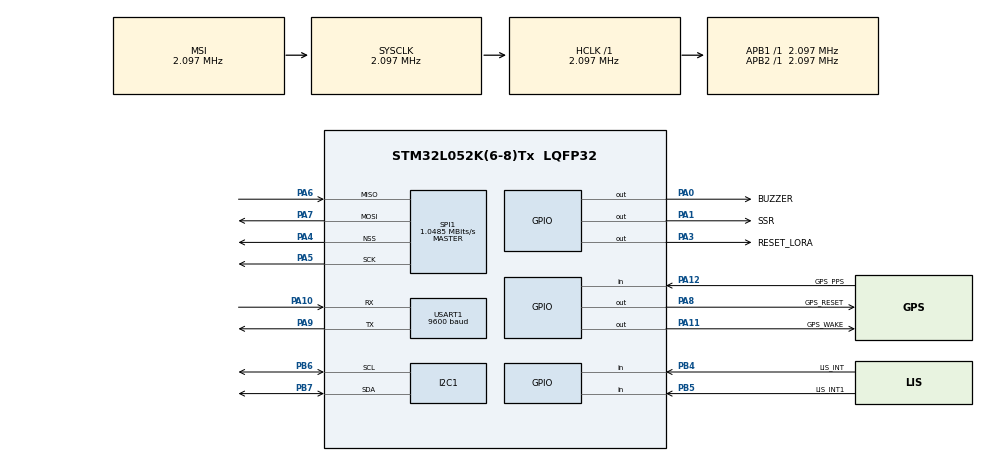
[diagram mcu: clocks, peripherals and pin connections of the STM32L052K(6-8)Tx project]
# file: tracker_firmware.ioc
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Mcu.Family=STM32L0
Mcu.Name=STM32L052K(6-8)Tx
Mcu.Package=LQFP32
PA0.GPIO_Label=BUZZER
PA0.GPIO_Speed=GPIO_SPEED_FREQ_VERY_HIGH
PA0.PinState=GPIO_PIN_RESET
PA0.Signal=GPIO_Output
PA1.GPIO_Label=SSR
PA1.GPIO_Speed=GPIO_SPEED_FREQ_VERY_HIGH
PA1.Signal=GPIO_Output
PA10.Mode=Multiprocessor_communication
PA10.Signal=USART1_RX
PA11.GPIO_Label=GPS_WAKE
PA11.Signal=GPIO_Output
PA12.GPIO_Label=GPS_PPS
PA12.Signal=GPIO_Input
PA13.Mode=Serial_Wire
PA13.Signal=SYS_SWDIO
PA14.Mode=Serial_Wire
PA14.Signal=SYS_SWCLK
PA3.GPIO_Label=RESET_LORA
PA3.Signal=GPIO_Output
PA4.Mode=NSS_Signal_Hard_Output
PA4.Signal=SPI1_NSS
PA5.Mode=Full_Duplex_Master
PA5.Signal=SPI1_SCK
PA6.Mode=Full_Duplex_Master
PA6.Signal=SPI1_MISO
PA7.Mode=Full_Duplex_Master
PA7.Signal=SPI1_MOSI
PA8.GPIO_Label=GPS_RESET
PA8.Signal=GPIO_Output
PA9.Mode=Multiprocessor_communication
PA9.Signal=USART1_TX
PB4.GPIO_Label=LIS_INT
PB4.Signal=GPIO_Input
PB5.GPIO_Label=LIS_INT1
PB5.Signal=GPIO_Input
PB6.GPIO_Pu=GPIO_PULLUP
PB6.Mode=I2C
PB6.Signal=I2C1_SCL
PB7.GPIO_Pu=GPIO_PULLUP
PB7.Mode=I2C
PB7.Signal=I2C1_SDA
PC14-OSC32_IN.Mode=LSE-External-Oscillator
PC14-OSC32_IN.Signal=RCC_OSC32_IN
PC15-OSC32_OUT.Mode=LSE-External-Oscillator
PC15-OSC32_OUT.Signal=RCC_OSC32_OUT
ProjectManager.HeapSize=0x200
ProjectManager.StackSize=0x400
ProjectManager.TargetToolchain=STM32CubeIDE
RCC.AHBFreq_Value=2097000
RCC.APB1Freq_Value=2097000
RCC.APB1TimFreq_Value=2097000
RCC.APB2Freq_Value=2097000
RCC.APB2TimFreq_Value=2097000
RCC.HSI16_VALUE=16000000
RCC.HSI48_VALUE=48000000
RCC.HSI_VALUE=16000000
RCC.MSI_VALUE=2097000
RCC.SYSCLKFreq_VALUE=2097000
RCC.VCOOutputFreq_Value=48000000
SPI1.CalculateBaudRate=1.0485 MBits/s
SPI1.Direction=SPI_DIRECTION_2LINES
SPI1.Mode=SPI_MODE_MASTER
SPI1.VirtualNSS=VM_NSSHARD
SPI1.VirtualType=VM_MASTER
USART1.BaudRate=9600
USART1.VirtualMode-Multiprocessor_communication=VM_ASYNC
VP_RTC_VS_RTC_Activate.Mode=RTC_Enabled
VP_RTC_VS_RTC_Calendar.Mode=RTC_Calendar
board=custom

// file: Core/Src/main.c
/* USER CODE BEGIN Header */
/**
  ******************************************************************************
  * @file           : main.c
  * @brief          : Main program body
  ******************************************************************************
  * @attention
  *
  * <h2><center>&copy; Copyright (c) 2021 STMicroelectronics.
  * All rights reserved.</center></h2>
  *
  * This software component is licensed by ST under BSD 3-Clause license,
  * the "License"; You may not use this file except in compliance with the
  * License. You may obtain a copy of the License at:
  *                        opensource.org/licenses/BSD-3-Clause
  *
  ******************************************************************************
  */
/* USER CODE END Header */
#include "main.h"
#include "tracker.h"

I2C_HandleTypeDef hi2c1;

RTC_HandleTypeDef hrtc;

SPI_HandleTypeDef hspi1;

UART_HandleTypeDef huart1;

void SystemClock_Config(void);
static void MX_GPIO_Init(void);
static void MX_I2C1_Init(void);
static void MX_RTC_Init(void);
static void MX_SPI1_Init(void);
static void MX_USART1_UART_Init(void);

int main(void)
{

  /* MCU Configuration--------------------------------------------------------*/

  /* Reset of all peripherals, Initializes the Flash interface and the Systick. */
  HAL_Init();

  /* Configure the system clock */
  SystemClock_Config();

  /* Initialize all configured peripherals */
  MX_GPIO_Init();
  MX_I2C1_Init();
  MX_RTC_Init();
  MX_SPI1_Init();
  MX_USART1_UART_Init();
  /* USER CODE BEGIN 2 */
  int errorcode = SetTime(0X0, 0X1, 0X0, 0X1, 0X9, 0X1, 0X1);

  /* USER CODE END 2 */

  /* Infinite loop */
  while (1)
  {

  }
}

void SystemClock_Config(void)
{
  RCC_OscInitTypeDef RCC_OscInitStruct = {0};
  RCC_ClkInitTypeDef RCC_ClkInitStruct = {0};
  RCC_PeriphCLKInitTypeDef PeriphClkInit = {0};

  /** Configure the main internal regulator output voltage
  */
  __HAL_PWR_VOLTAGESCALING_CONFIG(PWR_REGULATOR_VOLTAGE_SCALE1);
  /** Initializes the RCC Oscillators according to the specified parameters
  * in the RCC_OscInitTypeDef structure.
  */
  RCC_OscInitStruct.OscillatorType = RCC_OSCILLATORTYPE_LSI|RCC_OSCILLATORTYPE_MSI;
  RCC_OscInitStruct.LSIState = RCC_LSI_ON;
  RCC_OscInitStruct.MSIState = RCC_MSI_ON;
  RCC_OscInitStruct.MSICalibrationValue = 0;
  RCC_OscInitStruct.MSIClockRange = RCC_MSIRANGE_5;
  RCC_OscInitStruct.PLL.PLLState = RCC_PLL_NONE;
  if (HAL_RCC_OscConfig(&RCC_OscInitStruct) != HAL_OK)
  {
    Error_Handler();
  }
  /** Initializes the CPU, AHB and APB buses clocks
  */
  RCC_ClkInitStruct.ClockType = RCC_CLOCKTYPE_HCLK|RCC_CLOCKTYPE_SYSCLK
                              |RCC_CLOCKTYPE_PCLK1|RCC_CLOCKTYPE_PCLK2;
  RCC_ClkInitStruct.SYSCLKSource = RCC_SYSCLKSOURCE_MSI;
  RCC_ClkInitStruct.AHBCLKDivider = RCC_SYSCLK_DIV1;
  RCC_ClkInitStruct.APB1CLKDivider = RCC_HCLK_DIV1;
  RCC_ClkInitStruct.APB2CLKDivider = RCC_HCLK_DIV1;

  if (HAL_RCC_ClockConfig(&RCC_ClkInitStruct, FLASH_LATENCY_0) != HAL_OK)
  {
    Error_Handler();
  }
  PeriphClkInit.PeriphClockSelection = RCC_PERIPHCLK_USART1|RCC_PERIPHCLK_I2C1
                              |RCC_PERIPHCLK_RTC;
  PeriphClkInit.Usart1ClockSelection = RCC_USART1CLKSOURCE_PCLK2;
  PeriphClkInit.I2c1ClockSelection = RCC_I2C1CLKSOURCE_PCLK1;
  PeriphClkInit.RTCClockSelection = RCC_RTCCLKSOURCE_LSI;
  if (HAL_RCCEx_PeriphCLKConfig(&PeriphClkInit) != HAL_OK)
  {
    Error_Handler();
  }
}

static void MX_I2C1_Init(void)
{

  hi2c1.Instance = I2C1;
  hi2c1.Init.Timing = 0x00000708;
  hi2c1.Init.OwnAddress1 = 0;
  hi2c1.Init.AddressingMode = I2C_ADDRESSINGMODE_7BIT;
  hi2c1.Init.DualAddressMode = I2C_DUALADDRESS_DISABLE;
  hi2c1.Init.OwnAddress2 = 0;
  hi2c1.Init.OwnAddress2Masks = I2C_OA2_NOMASK;
  hi2c1.Init.GeneralCallMode = I2C_GENERALCALL_DISABLE;
  hi2c1.Init.NoStretchMode = I2C_NOSTRETCH_DISABLE;
  if (HAL_I2C_Init(&hi2c1) != HAL_OK)
  {
    Error_Handler();
  }
  /** Configure Analogue filter
  */
  if (HAL_I2CEx_ConfigAnalogFilter(&hi2c1, I2C_ANALOGFILTER_ENABLE) != HAL_OK)
  {
    Error_Handler();
  }
  /** Configure Digital filter
  */
  if (HAL_I2CEx_ConfigDigitalFilter(&hi2c1, 0) != HAL_OK)
  {
    Error_Handler();
  }

}

static void MX_RTC_Init(void)
{

  RTC_TimeTypeDef sTime = {0};
  RTC_DateTypeDef sDate = {0};

  /** Initialize RTC Only
  */
  hrtc.Instance = RTC;
  hrtc.Init.HourFormat = RTC_HOURFORMAT_24;
  hrtc.Init.AsynchPrediv = 127;
  hrtc.Init.SynchPrediv = 255;
  hrtc.Init.OutPut = RTC_OUTPUT_DISABLE;
  hrtc.Init.OutPutRemap = RTC_OUTPUT_REMAP_NONE;
  hrtc.Init.OutPutPolarity = RTC_OUTPUT_POLARITY_HIGH;
  hrtc.Init.OutPutType = RTC_OUTPUT_TYPE_OPENDRAIN;
  if (HAL_RTC_Init(&hrtc) != HAL_OK)
  {
    Error_Handler();
  }

  /** Initialize RTC and set the Time and Date
  */
  sTime.Hours = 0x0;
  sTime.Minutes = 0x0;
  sTime.Seconds = 0x0;
  sTime.DayLightSaving = RTC_DAYLIGHTSAVING_NONE;
  sTime.StoreOperation = RTC_STOREOPERATION_RESET;
  if (HAL_RTC_SetTime(&hrtc, &sTime, RTC_FORMAT_BCD) != HAL_OK)
  {
    Error_Handler();
  }
  sDate.WeekDay = RTC_WEEKDAY_MONDAY;
  sDate.Month = RTC_MONTH_JANUARY;
  sDate.Date = 0x1;
  sDate.Year = 0x0;

  if (HAL_RTC_SetDate(&hrtc, &sDate, RTC_FORMAT_BCD) != HAL_OK)
  {
    Error_Handler();
  }

}

static void MX_SPI1_Init(void)
{

  /* SPI1 parameter configuration*/
  hspi1.Instance = SPI1;
  hspi1.Init.Mode = SPI_MODE_MASTER;
  hspi1.Init.Direction = SPI_DIRECTION_2LINES;
  hspi1.Init.DataSize = SPI_DATASIZE_8BIT;
  hspi1.Init.CLKPolarity = SPI_POLARITY_LOW;
  hspi1.Init.CLKPhase = SPI_PHASE_1EDGE;
  hspi1.Init.NSS = SPI_NSS_HARD_OUTPUT;
  hspi1.Init.BaudRatePrescaler = SPI_BAUDRATEPRESCALER_2;
  hspi1.Init.FirstBit = SPI_FIRSTBIT_MSB;
  hspi1.Init.TIMode = SPI_TIMODE_DISABLE;
  hspi1.Init.CRCCalculation = SPI_CRCCALCULATION_DISABLE;
  hspi1.Init.CRCPolynomial = 7;
  if (HAL_SPI_Init(&hspi1) != HAL_OK)
  {
    Error_Handler();
  }

}

static void MX_USART1_UART_Init(void)
{

  huart1.Instance = USART1;
  huart1.Init.BaudRate = 9600;
  huart1.Init.WordLength = UART_WORDLENGTH_8B;
  huart1.Init.StopBits = UART_STOPBITS_1;
  huart1.Init.Parity = UART_PARITY_NONE;
  huart1.Init.Mode = UART_MODE_TX_RX;
  huart1.Init.HwFlowCtl = UART_HWCONTROL_NONE;
  huart1.Init.OverSampling = UART_OVERSAMPLING_16;
  huart1.Init.OneBitSampling = UART_ONE_BIT_SAMPLE_DISABLE;
  huart1.AdvancedInit.AdvFeatureInit = UART_ADVFEATURE_NO_INIT;
  if (HAL_MultiProcessor_Init(&huart1, 0, UART_WAKEUPMETHOD_IDLELINE) != HAL_OK)
  {
    Error_Handler();
  }

}

static void MX_GPIO_Init(void)
{
  GPIO_InitTypeDef GPIO_InitStruct = {0};

  /* GPIO Ports Clock Enable */
  __HAL_RCC_GPIOC_CLK_ENABLE();
  __HAL_RCC_GPIOA_CLK_ENABLE();
  __HAL_RCC_GPIOB_CLK_ENABLE();

  /*Configure GPIO pin Output Level */
  HAL_GPIO_WritePin(GPIOA, BUZZER_Pin|SSR_Pin|RESET_LORA_Pin|GPS_RESET_Pin
                          |GPS_WAKE_Pin, GPIO_PIN_RESET);

  /*Configure GPIO pins : BUZZER_Pin SSR_Pin */
  GPIO_InitStruct.Pin = BUZZER_Pin|SSR_Pin;
  GPIO_InitStruct.Mode = GPIO_MODE_OUTPUT_PP;
  GPIO_InitStruct.Pull = GPIO_NOPULL;
  GPIO_InitStruct.Speed = GPIO_SPEED_FREQ_VERY_HIGH;
  HAL_GPIO_Init(GPIOA, &GPIO_InitStruct);

  /*Configure GPIO pins : RESET_LORA_Pin GPS_RESET_Pin GPS_WAKE_Pin */
  GPIO_InitStruct.Pin = RESET_LORA_Pin|GPS_RESET_Pin|GPS_WAKE_Pin;
  GPIO_InitStruct.Mode = GPIO_MODE_OUTPUT_PP;
  GPIO_InitStruct.Pull = GPIO_NOPULL;
  GPIO_InitStruct.Speed = GPIO_SPEED_FREQ_LOW;
  HAL_GPIO_Init(GPIOA, &GPIO_InitStruct);

  /*Configure GPIO pin : GPS_PPS_Pin */
  GPIO_InitStruct.Pin = GPS_PPS_Pin;
  GPIO_InitStruct.Mode = GPIO_MODE_INPUT;
  GPIO_InitStruct.Pull = GPIO_NOPULL;
  HAL_GPIO_Init(GPS_PPS_GPIO_Port, &GPIO_InitStruct);

  /*Configure GPIO pins : LIS_INT_Pin LIS_INT1_Pin */
  GPIO_InitStruct.Pin = LIS_INT_Pin|LIS_INT1_Pin;
  GPIO_InitStruct.Mode = GPIO_MODE_INPUT;
  GPIO_InitStruct.Pull = GPIO_NOPULL;
  HAL_GPIO_Init(GPIOB, &GPIO_InitStruct);

}

void Error_Handler(void)
{
  __disable_irq();
  while (1)
  {
  }
}

/************************ (C) COPYRIGHT STMicroelectronics *****END OF FILE****/
